# SIM3L167_C register map
File version: 1
CPU: 
Registers are 32-bit, read-write, reset 0x0 unless marked. A register's access mark holds for its fields unless they carry their own. Offsets are from the block's base; [hi:lo] are bit positions.

## RSTSRC_0
Base 0x4002C000
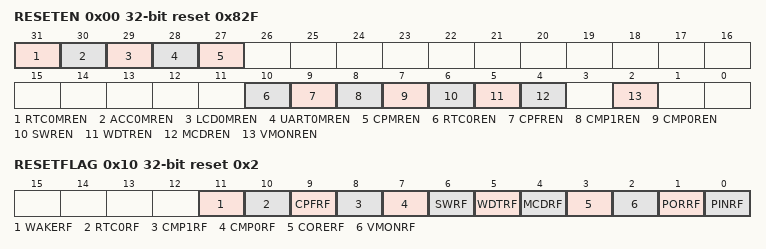
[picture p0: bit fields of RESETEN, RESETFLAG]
0x00 RESETEN reset 0x82F — System Reset Source Enable
  [31] RTC0MREN — RTC0 Module Reset Enable.
    0=DISABLED (Disable RTC0 module resets.); 1=ENABLED (Enable RTC0 module resets.)
  [30] ACC0MREN — ACCTR0 Module Reset Enable.
    0=DISABLED (Disable ACCTR0 module resets.); 1=ENABLED (Enable ACCTR0 module resets.)
  [29] LCD0MREN — LCD0 Module Reset Enable.
    0=DISABLED (Disable LCD0 module resets.); 1=ENABLED (Enable LCD0 module resets.)
  [28] UART0MREN — UART0 Module Reset Enable.
    0=DISABLED (Disable UART0 module resets.); 1=ENABLED (Enable UART0 module resets.)
  [27] CPMREN — Low Power Mode Charge Pump Module Reset Enable.
    0=DISABLED (Disable low power mode charge pump module resets.); 1=ENABLED (Enable low power mode charge pump module resets.)
  [10] RTC0REN — RTC0 Reset Enable.
    0=DISABLED (Disable the RTC0 event as a reset source.); 1=ENABLED (Enable the RTC0 event as a reset source.)
  [9] CPFREN — Low Power Mode Charge Pump Supply Fail Reset Enable.
    0=DISABLED (Disable the low power mode charge pump supply fail event as a reset source.); 1=ENABLED (Enable the low power mode charge pump supply fail event as a reset source.)
  [8] CMP1REN — Comparator 1 Reset Enable.
    0=DISABLED (Disable the Comparator 1 event as a reset source.); 1=ENABLED (Enable the Comparator 1 event as a reset source.)
  [7] CMP0REN — Comparator 0 Reset Enable.
    0=DISABLED (Disable the Comparator 0 event as a reset source.); 1=ENABLED (Enable the Comparator 0 event as a reset source.)
  [6] SWREN — Software Reset.
    0=DISABLED (Do not generate a Software Reset.); 1=ENABLED (Generate a Software Reset.)
  [5] WDTREN — Watchdog Timer Reset Enable.
    0=DISABLED (Disable the Watchdog Timer event as a reset source.); 1=ENABLED (Enable the Watchdog Timer event as a reset source.)
  [4] MCDREN — Missing Clock Detector Reset Enable.
    0=DISABLED (Disable the Missing Clock Detector event as a reset source.); 1=ENABLED (Enable the Missing Clock Detector event as a reset source.)
  [2] VMONREN — Voltage Supply Monitor VBAT Reset Enable.
    0=DISABLED (Disable the Voltage Supply Monitor VBAT event as a reset source.); 1=ENABLED (Enable the Voltage Supply Monitor VBAT event as a reset source.)
0x10 RESETFLAG reset 0x2 — System Reset Flags
  [11] WAKERF ro — PMU Wakeup Reset Flag.
    0=NOT_SET (A PMU Wakeup event did not cause the last system reset.); 1=SET (A PMU Wakeup event caused the last system reset.)
  [10] RTC0RF ro — RTC0 Reset Flag.
    0=NOT_SET (An RTC0 event did not cause the last system reset.); 1=SET (An RTC0 event caused the last system reset.)
  [9] CPFRF ro — Low Power Mode Charge Pump Supply Fail Reset Flag.
    0=NOT_SET (A low power mode charge pump supply fail event did not cause the last system reset.); 1=SET (A low power mode charge pump supply fail event caused the last system reset.)
  [8] CMP1RF ro — Comparator 1 Reset Flag.
    0=NOT_SET (A Comparator 1 event did not cause the last system reset.); 1=SET (A Comparator 1 event caused the last system reset.)
  [7] CMP0RF ro — Comparator 0 Reset Flag.
    0=NOT_SET (A Comparator 0 event did not cause the last system reset.); 1=SET (A Comparator 0 event caused the last system reset.)
  [6] SWRF ro — Software Reset Flag.
    0=NOT_SET (A Software Reset event did not cause the last system reset.); 1=SET (A Software Reset event caused the last system reset.)
  [5] WDTRF ro — Watchdog Timer Reset Flag.
    0=NOT_SET (A Watchdog Timer event did not cause the last system reset.); 1=SET (A Watchdog Timer event caused the last system reset.)
  [4] MCDRF ro — Missing Clock Detector Reset Flag.
    0=NOT_SET (A Missing Clock Detector event did not cause the last system reset.); 1=SET (A Missing Clock Detector event caused the last system reset.)
  [3] CORERF ro — Core Reset Flag.
    0=NOT_SET (A Core Reset event did not cause the last system reset.); 1=SET (A Core Reset event caused the last system reset.)
  [2] VMONRF ro — Voltage Supply Monitor VBAT Reset Flag.
    0=NOT_SET (A Voltage Supply Monitor VBAT Reset event did not cause the last system reset.); 1=SET (A Voltage Supply Monitor VBAT Reset event caused the last system reset.)
  [1] PORRF ro — Power-On Reset Flag.
    0=NOT_SET (A Power-On Reset event did not cause the last system reset.); 1=SET (A Power-On Reset event caused the last system reset.)
  [0] PINRF ro — Pin Reset Flag.
    0=NOT_SET (A /RESET pin event did not cause the last system reset.); 1=SET (A /RESET pin event caused the last system reset.)
